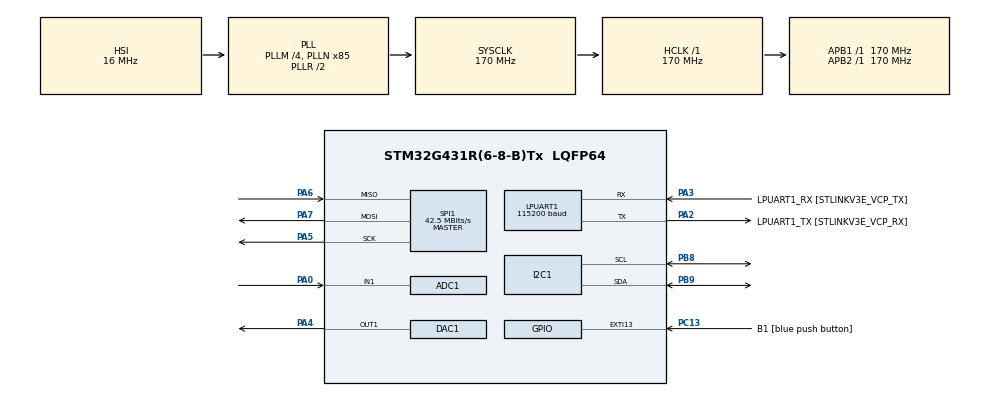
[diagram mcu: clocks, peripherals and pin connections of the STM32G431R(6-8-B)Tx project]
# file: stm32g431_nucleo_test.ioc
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ADC1.Channel-0\#ChannelRegularConversion=ADC_CHANNEL_1
ADC1.NbrOfConversionFlag=1
ADC1.OffsetNumber-0\#ChannelRegularConversion=ADC_OFFSET_NONE
ADC1.Rank-0\#ChannelRegularConversion=1
ADC1.SamplingTime-0\#ChannelRegularConversion=ADC_SAMPLETIME_2CYCLES_5
ADC1.master=1
DAC1.DAC_HighFrequency_OUT1-DAC_OUT1=DAC_HIGH_FREQUENCY_INTERFACE_MODE_AUTOMATIC
DAC1.DAC_OutputBuffer-DAC_OUT1=DAC_OUTPUTBUFFER_ENABLE
DAC1.DAC_SignedFormat-DAC_OUT1=DISABLE
DAC1.DAC_Trigger_OUT1-DAC_OUT1=DAC_TRIGGER_NONE
Dma.ADC1.0.Direction=DMA_PERIPH_TO_MEMORY
Dma.ADC1.0.EventEnable=DISABLE
Dma.ADC1.0.Instance=DMA1_Channel1
Dma.ADC1.0.MemDataAlignment=DMA_MDATAALIGN_HALFWORD
Dma.ADC1.0.MemInc=DMA_MINC_ENABLE
Dma.ADC1.0.Mode=DMA_CIRCULAR
Dma.ADC1.0.PeriphDataAlignment=DMA_PDATAALIGN_HALFWORD
Dma.ADC1.0.PeriphInc=DMA_PINC_DISABLE
Dma.ADC1.0.Polarity=HAL_DMAMUX_REQ_GEN_RISING
Dma.ADC1.0.Priority=DMA_PRIORITY_LOW
Dma.ADC1.0.RequestNumber=1
Dma.ADC1.0.SignalID=NONE
Dma.ADC1.0.SyncEnable=DISABLE
Dma.ADC1.0.SyncPolarity=HAL_DMAMUX_SYNC_NO_EVENT
Dma.ADC1.0.SyncRequestNumber=1
Dma.ADC1.0.SyncSignalID=NONE
Dma.Request0=ADC1
FREERTOS.HEAP_NUMBER=3
FREERTOS.Tasks01=defaultTask,0,128,StartDefaultTask,Default,NULL,Dynamic,NULL,NULL
FREERTOS.configENABLE_FPU=1
I2C1.Timing=0x30A0A7FB
LPUART1.BaudRate=115200
LPUART1.WordLength=UART_WORDLENGTH_8B
Mcu.Family=STM32G4
Mcu.Name=STM32G431R(6-8-B)Tx
Mcu.Package=LQFP64
NVIC.ADC1_2_IRQn=true\:5\:0\:false\:false\:true\:true\:true\:true\:true
NVIC.DMA1_Channel1_IRQn=true\:5\:0\:false\:false\:true\:true\:false\:true\:true
NVIC.LPUART1_IRQn=true\:5\:0\:false\:false\:true\:true\:true\:true\:true
NVIC.PriorityGroup=NVIC_PRIORITYGROUP_4
NVIC.TIM1_UP_TIM16_IRQn=true\:15\:0\:false\:false\:true\:false\:false\:true\:true
NVIC.TimeBase=TIM1_UP_TIM16_IRQn
NVIC.TimeBaseIP=TIM1
PA0.Mode=IN1-Single-Ended
PA0.Signal=ADC1_IN1
PA13.GPIO_Label=T_SWDIO
PA13.Mode=Serial_Wire
PA13.Signal=SYS_JTMS-SWDIO
PA14.GPIO_Label=T_SWCLK
PA14.Mode=Serial_Wire
PA14.Signal=SYS_JTCK-SWCLK
PA2.GPIO_Label=LPUART1_TX [STLINKV3E_VCP_RX]
PA2.Mode=Asynchronous
PA2.Signal=LPUART1_TX
PA3.GPIO_Label=LPUART1_RX [STLINKV3E_VCP_TX]
PA3.Mode=Asynchronous
PA3.Signal=LPUART1_RX
PA4.Signal=COMP_DAC11_group
PA5.Mode=Full_Duplex_Master
PA5.Signal=SPI1_SCK
PA6.Mode=Full_Duplex_Master
PA6.Signal=SPI1_MISO
PA7.Mode=Full_Duplex_Master
PA7.Signal=SPI1_MOSI
PB3.GPIO_Label=T_SWO
PB3.Signal=SYS_JTDO-SWO
PB8-BOOT0.Mode=I2C
PB8-BOOT0.Signal=I2C1_SCL
PB9.Mode=I2C
PB9.Signal=I2C1_SDA
PC13.GPIO_Label=B1 [blue push button]
PC13.Signal=GPXTI13
PC14-OSC32_IN.Mode=LSE-External-Oscillator
PC14-OSC32_IN.Signal=RCC_OSC32_IN
PC15-OSC32_OUT.Mode=LSE-External-Oscillator
PC15-OSC32_OUT.Signal=RCC_OSC32_OUT
PF0-OSC_IN.Mode=HSE-External-Oscillator
PF0-OSC_IN.Signal=RCC_OSC_IN
PF1-OSC_OUT.Mode=HSE-External-Oscillator
PF1-OSC_OUT.Signal=RCC_OSC_OUT
ProjectManager.HeapSize=0x200
ProjectManager.StackSize=0x400
ProjectManager.TargetToolchain=STM32CubeIDE
RCC.ADC12Freq_Value=170000000
RCC.AHBFreq_Value=170000000
RCC.APB1Freq_Value=170000000
RCC.APB1TimFreq_Value=170000000
RCC.APB2Freq_Value=170000000
RCC.APB2TimFreq_Value=170000000
RCC.CortexFreq_Value=170000000
RCC.EXTERNAL_CLOCK_VALUE=12288000
RCC.HCLKFreq_Value=170000000
RCC.HSE_VALUE=24000000
RCC.HSI48_VALUE=48000000
RCC.HSI_VALUE=16000000
RCC.PLLM=RCC_PLLM_DIV4
RCC.PLLN=85
RCC.RTCClockSelection=RCC_RTCCLKSOURCE_LSE
RCC.SYSCLKFreq_VALUE=170000000
RCC.SYSCLKSource=RCC_SYSCLKSOURCE_PLLCLK
RCC.USBFreq_Value=170000000
RCC.VCOOutputFreq_Value=340000000
SH.COMP_DAC11_group.0=DAC1_OUT1,DAC_OUT1
SPI1.BaudRatePrescaler=SPI_BAUDRATEPRESCALER_4
SPI1.CalculateBaudRate=42.5 MBits/s
SPI1.DataSize=SPI_DATASIZE_8BIT
SPI1.Direction=SPI_DIRECTION_2LINES
SPI1.Mode=SPI_MODE_MASTER
SPI1.VirtualType=VM_MASTER
VP_FREERTOS_VS_CMSIS_V1.Mode=CMSIS_V1
VP_SYS_VS_DBSignals.Mode=DisableDeadBatterySignals
VP_SYS_VS_tim1.Mode=TIM1
board=NUCLEO-G431RB

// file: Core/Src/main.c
/* USER CODE BEGIN Header */
/**
  ******************************************************************************
  * @file           : main.c
  * @brief          : Main program body
  ******************************************************************************
  * @attention
  *
  * Copyright (c) 2024 STMicroelectronics.
  * All rights reserved.
  *
  * This software is licensed under terms that can be found in the LICENSE file
  * in the root directory of this software component.
  * If no LICENSE file comes with this software, it is provided AS-IS.
  *
  ******************************************************************************
  */
/* USER CODE END Header */
#include "main.h"
#include "cmsis_os.h"
#include "adc.h"
#include "dac.h"
#include "dma.h"
#include "i2c.h"
#include "usart.h"
#include "spi.h"
#include "gpio.h"

/* USER CODE BEGIN Includes */
#include "cli_interface.h"
#include "flash_if.h"
/* USER CODE END Includes */

void SystemClock_Config(void);
void MX_FREERTOS_Init(void);

/* USER CODE BEGIN 0 */
#define _USE_APP_	1
/* USER CODE END 0 */

int main(void)
{

  /* MCU Configuration--------------------------------------------------------*/

  /* Reset of all peripherals, Initializes the Flash interface and the Systick. */
  HAL_Init();

  /* Configure the system clock */
  SystemClock_Config();

  /* Initialize all configured peripherals */
  MX_GPIO_Init();
#ifdef _USE_APP_
  MX_DMA_Init();
  MX_ADC1_Init();
  MX_I2C1_Init();
  MX_SPI1_Init();
  MX_DAC1_Init();
#endif
  MX_LPUART1_UART_Init();
  /* USER CODE BEGIN 2 */
  CLI_Init();

  /* USER CODE END 2 */

  /* Call init function for freertos objects (in cmsis_os2.c) */
  MX_FREERTOS_Init();

  /* Start scheduler */
  osKernelStart();

  /* We should never get here as control is now taken by the scheduler */

  /* Infinite loop */
  while (1)
  {

  }
}

void SystemClock_Config(void)
{
  RCC_OscInitTypeDef RCC_OscInitStruct = {0};
  RCC_ClkInitTypeDef RCC_ClkInitStruct = {0};

  /** Configure the main internal regulator output voltage
  */
  HAL_PWREx_ControlVoltageScaling(PWR_REGULATOR_VOLTAGE_SCALE1_BOOST);

  /** Initializes the RCC Oscillators according to the specified parameters
  * in the RCC_OscInitTypeDef structure.
  */
  RCC_OscInitStruct.OscillatorType = RCC_OSCILLATORTYPE_HSI;
  RCC_OscInitStruct.HSIState = RCC_HSI_ON;
  RCC_OscInitStruct.HSICalibrationValue = RCC_HSICALIBRATION_DEFAULT;
  RCC_OscInitStruct.PLL.PLLState = RCC_PLL_ON;
  RCC_OscInitStruct.PLL.PLLSource = RCC_PLLSOURCE_HSI;
  RCC_OscInitStruct.PLL.PLLM = RCC_PLLM_DIV4;
  RCC_OscInitStruct.PLL.PLLN = 85;
  RCC_OscInitStruct.PLL.PLLP = RCC_PLLP_DIV2;
  RCC_OscInitStruct.PLL.PLLQ = RCC_PLLQ_DIV2;
  RCC_OscInitStruct.PLL.PLLR = RCC_PLLR_DIV2;
  if (HAL_RCC_OscConfig(&RCC_OscInitStruct) != HAL_OK)
  {
    Error_Handler();
  }

  /** Initializes the CPU, AHB and APB buses clocks
  */
  RCC_ClkInitStruct.ClockType = RCC_CLOCKTYPE_HCLK|RCC_CLOCKTYPE_SYSCLK
                              |RCC_CLOCKTYPE_PCLK1|RCC_CLOCKTYPE_PCLK2;
  RCC_ClkInitStruct.SYSCLKSource = RCC_SYSCLKSOURCE_PLLCLK;
  RCC_ClkInitStruct.AHBCLKDivider = RCC_SYSCLK_DIV1;
  RCC_ClkInitStruct.APB1CLKDivider = RCC_HCLK_DIV1;
  RCC_ClkInitStruct.APB2CLKDivider = RCC_HCLK_DIV1;

  if (HAL_RCC_ClockConfig(&RCC_ClkInitStruct, FLASH_LATENCY_4) != HAL_OK)
  {
    Error_Handler();
  }
}

void HAL_TIM_PeriodElapsedCallback(TIM_HandleTypeDef *htim)
{
  if (htim->Instance == TIM1) {
    HAL_IncTick();
  }
}

void Error_Handler(void)
{
  __disable_irq();
  while (1)
  {
  }
}

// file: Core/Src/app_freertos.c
/* USER CODE BEGIN Header */
/**
  ******************************************************************************
  * File Name          : app_freertos.c
  * Description        : Code for freertos applications
  ******************************************************************************
  * @attention
  *
  * Copyright (c) 2024 STMicroelectronics.
  * All rights reserved.
  *
  * This software is licensed under terms that can be found in the LICENSE file
  * in the root directory of this software component.
  * If no LICENSE file comes with this software, it is provided AS-IS.
  *
  ******************************************************************************
  */
/* USER CODE END Header */

#include "FreeRTOS.h"
#include "task.h"
#include "main.h"
#include "cmsis_os.h"

/* USER CODE BEGIN Includes */
#include <stdio.h>

#include "cli_interface.h"
/* USER CODE END Includes */

osThreadId CLI_TaskHandle;

void CLI_Task(void const * argument);

void MX_FREERTOS_Init(void); /* (MISRA C 2004 rule 8.1) */

void MX_FREERTOS_Init(void)
{
  /* USER CODE BEGIN Init */
  CLI_Init();
  /* USER CODE END Init */

  /* Create the thread(s) */
  /* definition and creation of defaultTask */
  osThreadDef(defaultTask, CLI_Task, osPriorityNormal, 0, 128);
  CLI_TaskHandle = osThreadCreate(osThread(defaultTask), NULL);

}

void CLI_Task(void const * argument)
{
  /* USER CODE BEGIN StartDefaultTask */
  /* Infinite loop */
  for(;;)
  {
    if (cli.rx_done == CLI_READY) {
        cli.rx_done = CLI_CLEAR;
        parser((char *)&cli.buffer[0]);
    }
    osDelay(1);
  }
  /* USER CODE END StartDefaultTask */
}
